# EFR32FG25A221F1920IM56 register map
Vendor: Silicon Labs; Series: EFR32; File version: B
Registers are 32-bit, read-write, reset 0x0 unless marked. A register's access mark holds for its fields unless they carry their own. Offsets are from the block's base; [hi:lo] are bit positions; {n}, {i} and the like mark numbered series; 'fields as' and 'values as' point back to an identical list.

## DMEM_NS — DMEM_NS Registers
Base 0x500C0000
Same registers: DMEM_S 0x400C0000, MPAHBRAM_S 0xA6020000, MPAHBRAM_NS 0xB6020000
0x00 IPVERSION ro reset 0x2
  [1:0] IPVERSION — New BitField
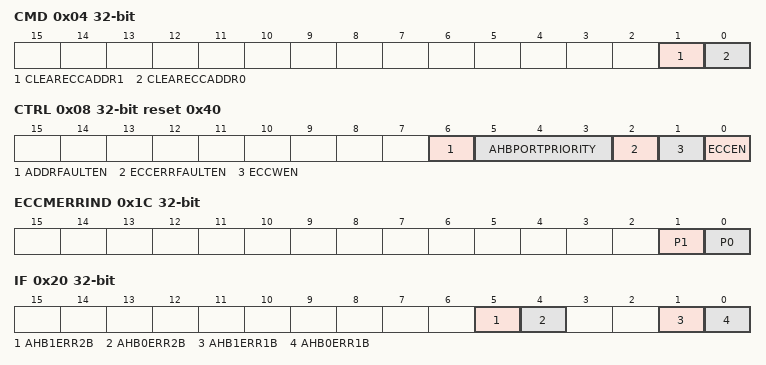
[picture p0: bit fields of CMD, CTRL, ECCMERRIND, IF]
0x04 CMD wo
  [1] CLEARECCADDR1 — Clear ECCERRADDR1
  [0] CLEARECCADDR0 — Clear ECCERRADDR0
0x08 CTRL reset 0x40
  [6] ADDRFAULTEN — Address fault bus fault enable
  [5:3] AHBPORTPRIORITY — AHB port arbitration priority
    0=NONE (No AHB port have raised priority.); 1=PORT0 (AHB port 0 has raised priority.); 2=PORT1 (AHB port 1 has raised priority.)
  [2] ECCERRFAULTEN — ECC Error bus fault enable
  [1] ECCWEN — Enable ECC syndrome writes
  [0] ECCEN — Enable ECC functionality
0x0C ECCERRADDR0 ro
  [31:0] ADDR — ECC Error Address
0x10 ECCERRADDR1 ro
  [31:0] ADDR — ECC Error Address
0x1C ECCMERRIND ro
  [1] P1 — Multiple ECC errors on AHB port 1
  [0] P0 — Multiple ECC errors on AHB port 0
0x20 IF
  [5] AHB1ERR2B — AHB1 2-bit ECC Error Interrupt Flag
  [4] AHB0ERR2B — AHB0 2-bit ECC Error Interrupt Flag
  [1] AHB1ERR1B — AHB1 1-bit ECC Error Interrupt Flag
  [0] AHB0ERR1B — AHB0 1-bit ECC Error Interrupt Flag
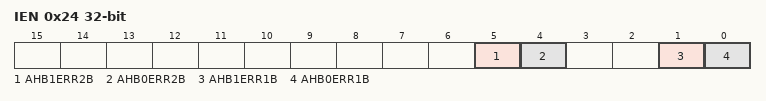
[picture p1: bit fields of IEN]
0x24 IEN
  [5] AHB1ERR2B — AHB1 2-bit ECC Error Interrupt Enable
  [4] AHB0ERR2B — AHB0 2-bit ECC Error Interrupt Enable
  [1] AHB1ERR1B — AHB1 1-bit ECC Error Interrupt Enable
  [0] AHB0ERR1B — AHB0 1-bit ECC Error Interrupt Enable

## DPLL0_NS — DPLL0_NS Registers
Base 0x5001C000
Same registers: DPLL0_S 0x4001C000
0x00 IPVERSION ro reset 0x1
  [31:0] IPVERSION — IP Version ID
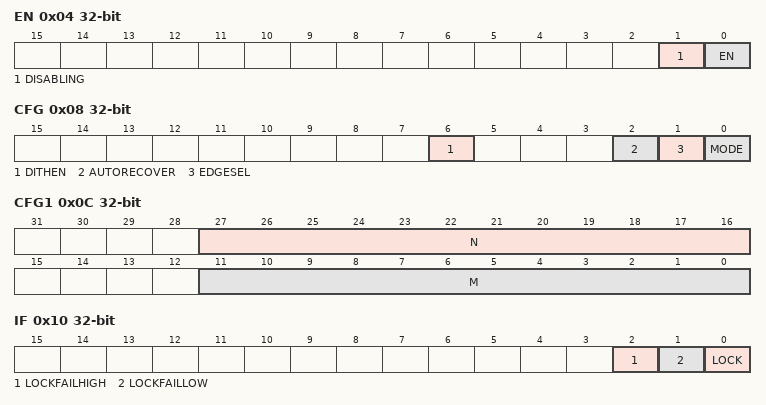
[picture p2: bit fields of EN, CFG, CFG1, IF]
0x04 EN
  [1] DISABLING ro — Disablement Busy Status
  [0] EN — Module Enable
0x08 CFG
  [6] DITHEN — Dither Enable Control
  [2] AUTORECOVER — Automatic Recovery Control
  [1] EDGESEL — Reference Edge Select
  [0] MODE — Operating Mode Control
    0=FLL (Frequency Lock Mode); 1=PLL (Phase Lock Mode)
0x0C CFG1
  [27:16] N — Factor N
  [11:0] M — Factor M
0x10 IF
  [2] LOCKFAILHIGH — Lock Failure High Interrupt Flag
  [1] LOCKFAILLOW — Lock Failure Low Interrupt Flag
  [0] LOCK — Lock Interrupt Flag
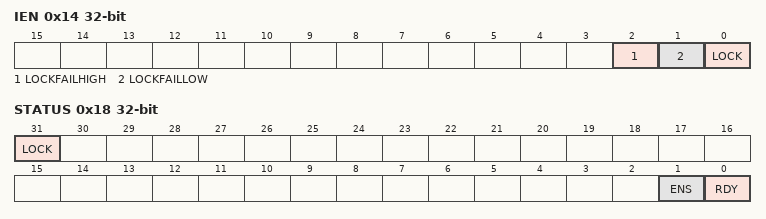
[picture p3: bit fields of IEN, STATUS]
0x14 IEN
  [2] LOCKFAILHIGH — LOCKFAILHIGH Interrupt Enable
  [1] LOCKFAILLOW — LOCKFAILLOW Interrupe Enable
  [0] LOCK — LOCK interrupt Enable
0x18 STATUS ro
  [31] LOCK — Lock Status
    0=UNLOCKED (DPLL is unlocked); 1=LOCKED (DPLL is locked)
  [1] ENS — Enable Status
  [0] RDY — Ready Status
0x24 LOCK wo reset 0x7102
  [15:0] LOCKKEY
    0x7102=UNLOCK (Unlock code)

## ETAMPDET_NS — ETAMPDET_NS Registers
Base 0x500D0000
Same registers: ETAMPDET_S 0x400D0000
0x00 IPVERSION ro reset 0x1
  [31:0] IPVERSION — IP Version ID
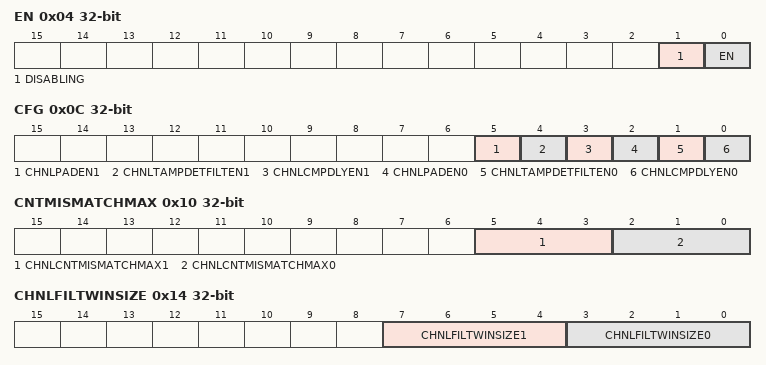
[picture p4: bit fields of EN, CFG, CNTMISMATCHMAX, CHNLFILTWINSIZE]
0x04 EN
  [1] DISABLING ro — Disablement busy status
  [0] EN — ETAMPDET Enable
0x0C CFG
  [5] CHNLPADEN1 — enable driving pad
    0=DISABLE (Disables channel 0 Tamper detect filtering feature); 1=ENABLE (Enables channel 0 Tamper detect filtering feature)
  [4] CHNLTAMPDETFILTEN1 — enable detect filtering
    0=DISABLE (Disables channel 1 Tamper detect filtering feature); 1=ENABLE (Enables channel 1 Tamper detect filtering feature)
  [3] CHNLCMPDLYEN1 — enable delay for comparison
    0=DISABLE (Disables 1 clock delay to the TX value used for comparison.); 1=ENABLE (Enables 1 clock delay to the TX value used for comparison.)
  [2] CHNLPADEN0 — enable driving pad
    values as CHNLPADEN1
  [1] CHNLTAMPDETFILTEN0 — enable detect filtering
    values as CHNLPADEN1
  [0] CHNLCMPDLYEN0 — enable delay for comparison
    0=Disables 1 clock delay to the TX value used for comparison; 1=Enables 1 clock delay to the TX value used for comparison
0x10 CNTMISMATCHMAX
  [5:3] CHNLCNTMISMATCHMAX1 — channel 1 filter counter threshold
    0=DetectFilterThreshold1 (Detect filter raise detect flag after seeing 1 event before reset counter expire); {v}=DetectFilterThreshold{v+1} (Detect filter raise detect flag after seeing {v+1} events before reset counter expire) (v=1..7)
  [2:0] CHNLCNTMISMATCHMAX0 — channel 0 filter counter threshold
    values as CHNLCNTMISMATCHMAX1
0x14 CHNLFILTWINSIZE
  [7:4] CHNLFILTWINSIZE1 — channel 1 Filter moving window size
    {v}=DetectFilterMovingWinSize{v+1} (Detect filter moving window size is {v+1}) (v=1..15)
  [3:0] CHNLFILTWINSIZE0 — channel 0 Filter moving window size
    values as CHNLFILTWINSIZE1
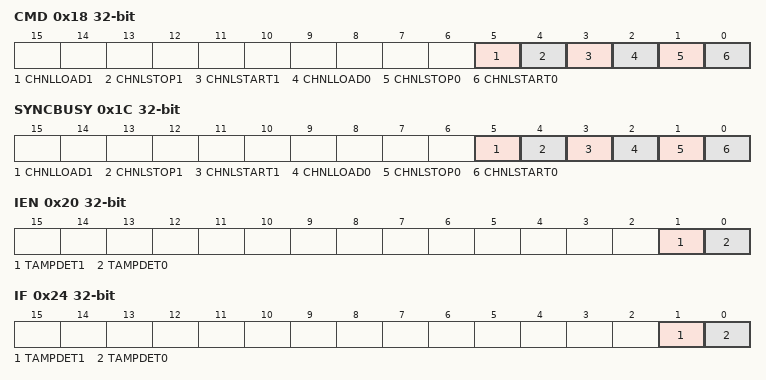
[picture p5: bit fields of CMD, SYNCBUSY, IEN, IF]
0x18 CMD wo
  [5] CHNLLOAD1 — Start channel 1 tamper detection
  [4] CHNLSTOP1 — Stop channel 1 tamper detection
  [3] CHNLSTART1 — Start channel 1 tamper detection
  [2] CHNLLOAD0 — Start channel 0 tamper detection
  [1] CHNLSTOP0 — Stop channel 0 tamper detection
  [0] CHNLSTART0 — Start channel 0 tamper detection
0x1C SYNCBUSY ro
  [5] CHNLLOAD1 — Synchronizer busy status
  [4] CHNLSTOP1 — Synchronizer busy status
  [3] CHNLSTART1 — Synchronizer busy status
  [2] CHNLLOAD0 — Synchronizer busy status
  [1] CHNLSTOP0 — Synchronizer busy status
  [0] CHNLSTART0 — Synchronizer busy status
0x20 IEN
  [1] TAMPDET1 — TAMPDET1 interrupt enable
  [0] TAMPDET0 — TAMPDET0 interrupt enable
0x24 IF
  [1] TAMPDET1 — Tamper1 Detect Flag
  [0] TAMPDET0 — Tamper0 Detect Flag
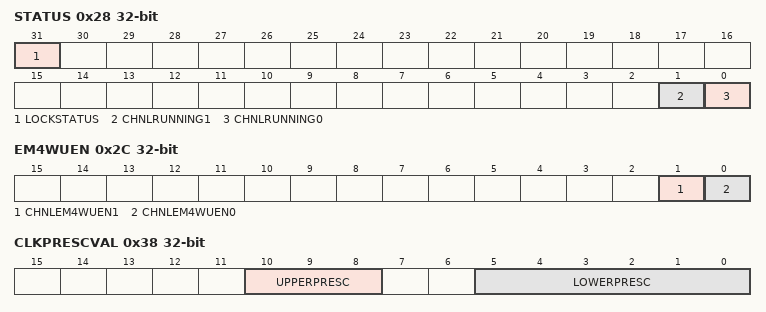
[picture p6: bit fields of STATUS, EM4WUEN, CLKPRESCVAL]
0x28 STATUS ro
  [31] LOCKSTATUS
    0=UNLOCKED (ETAMPDET registers are unlocked); 1=LOCKED (ETAMPDET registers are locked)
  [1] CHNLRUNNING1 — Channel1 Running Status
  [0] CHNLRUNNING0 — Channel0 Running Status
0x2C EM4WUEN
  [1] CHNLEM4WUEN1 — Channel1 Tampdet EM4 Wakeup Enable
  [0] CHNLEM4WUEN0 — Channel0 Tampdet EM4 Wakeup Enable
0x30 CHNLSEEDVAL0
  [31:0] CHNLSEEDVAL0 — Channel 0 LFSR Seed Value
0x34 CHNLSEEDVAL1
  [31:0] CHNLSEEDVAL1 — Channel 1 LFSR Seed Value
0x38 CLKPRESCVAL — Finial dividing factor = RIPPLECNTUPPER * CNTLOWER
  [10:8] UPPERPRESC — Upper part of divider ripple counter
    0=Bypass (Ripple counter divider is bypassed); 1=DivideBy2; 2=DivideBy4; 3=DivideBy8; 4=DivideBy16; 5=DivideBy32; 6=DivideBy64
  [5:0] LOWERPRESC — Lower part of divider binary counter
    0=Bypass (Divider is bypassed); {v}=DivideBy{v+1} (v=1..63)
0x48 LOCK wo reset 0xAEE8
  [15:0] LOCKKEY — Configuration Lock Key
    0xAEE8=UNLOCK (Write to unlock all BURTC lockable registers)
